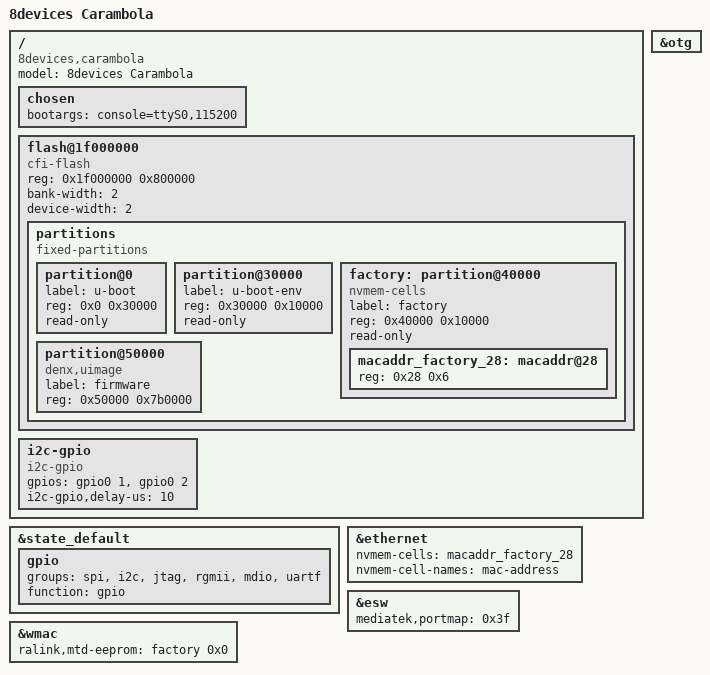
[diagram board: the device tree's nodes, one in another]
#include "rt3050.dtsi"

#include <dt-bindings/gpio/gpio.h>
#include <dt-bindings/input/input.h>

/ {
	compatible = "8devices,carambola", "ralink,rt3050-soc";
	model = "8devices Carambola";

	chosen {
		bootargs = "console=ttyS0,115200";
	};

	flash@1f000000 {
		compatible = "cfi-flash";
		reg = <0x1f000000 0x800000>;
		bank-width = <2>;
		device-width = <2>;

		partitions {
			compatible = "fixed-partitions";
			#address-cells = <1>;
			#size-cells = <1>;

			partition@0 {
				label = "u-boot";
				reg = <0x0 0x30000>;
				read-only;
			};

			partition@30000 {
				label = "u-boot-env";
				reg = <0x30000 0x10000>;
				read-only;
			};

			factory: partition@40000 {
				label = "factory";
				reg = <0x40000 0x10000>;
				read-only;
			};

			partition@50000 {
				compatible = "denx,uimage";
				label = "firmware";
				reg = <0x50000 0x7b0000>;
			};
		};
	};

	i2c-gpio {
		compatible = "i2c-gpio";
		gpios = <&gpio0 1 GPIO_ACTIVE_HIGH &gpio0 2 GPIO_ACTIVE_HIGH>;
		i2c-gpio,delay-us = <10>;
	};
};

&state_default {
	gpio {
		groups = "spi", "i2c", "jtag", "rgmii", "mdio", "uartf";
		function = "gpio";
	};
};

&ethernet {
	nvmem-cells = <&macaddr_factory_28>;
	nvmem-cell-names = "mac-address";
};

&esw {
	mediatek,portmap = <0x3f>;
};

&wmac {
	ralink,mtd-eeprom = <&factory 0x0>;
};

&otg {
	status = "okay";
};

&factory {
	compatible = "nvmem-cells";
	#address-cells = <1>;
	#size-cells = <1>;

	macaddr_factory_28: macaddr@28 {
		reg = <0x28 0x6>;
	};
};
